# M5531 register map
File version: 1.0
Registers are 32-bit, read-write, reset 0x0 unless marked. A register's access mark holds for its fields unless they carry their own. Offsets are from the block's base; [hi:lo] are bit positions; {n}, {i} and the like mark numbered series; 'fields as' and 'values as' point back to an identical list.

## TRNG_NS — TRNG Register Map
Base 0x50296000
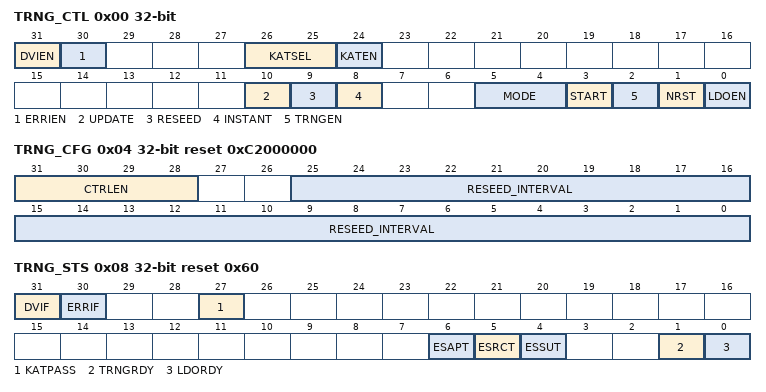
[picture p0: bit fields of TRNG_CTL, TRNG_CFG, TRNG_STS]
0x00 TRNG_CTL — TRNG Control Register
  [31] DVIEN — Data Valid Interrupt Enable Bit
    0=Interrupt Disabled; 1=Interrupt Enabled
  [30] ERRIEN — TRNG Error Interrupt Enable Bit
    0=Error interrupt Disabled; 1=Error interrupt Enabled
  [26:25] KATSEL — CTR_DRBG Known Answer Test Selection
    0=Instantiation testing; 1=Reseed testing; 2=Generation testing
  [24] KATEN — CTR_DRBG Known Answer Test Enable Bit. Note: Do not enable START and KATEN at the same time.
    0=Disabled; 1=Enabled
  [10] UPDATE — CTR_DRBG User Manual Update Function
    0=No effect; 1=Enable CTR_DRBG update function
  [9] RESEED — CTR_DRBG User Manual Reseed Function
    0=No effect; 1=Enable CTR_DRBG reseed function
  [8] INSTANT — CTR_DRBG User Manual Instant Function
    0=No effect; 1=Enable CTR_DRBG instant function
  [5:4] MODE — Random Bit Generator Output Selection
    0=Output data is from entropy (32-bits); 1=Output data is from NRBG (128-bits); 2=Output data is from DRBG (128-bits)
  [3] START — True Random Number Generator Start. Note: Do not enable START and KATEN at the same time. This bit is always 0 when it is read back.
    0=No effect; 1=Start TRNG
  [2] TRNGEN — True Random Number Generator Macro Enable Bit
    0=TRNG macro Disabled; 1=TRNG macro Enabled
  [1] NRST — Negative-edge Trigger Reset
    0=Keep reset; 1=No reset
  [0] LDOEN — LDO Enable Bit
    0=LDO Disabled; 1=LDO Enabled
0x04 TRNG_CFG reset 0xC2000000 — TRNG Configure Register
  [31:28] CTRLEN — CTR_DRBG Bits Length Per Request
  [25:0] RESEED_INTERVAL — Reseed Interval. Maximum number of requests between reseeds. The value is 1 ~ 225 .
0x08 TRNG_STS ro reset 0x60 — TRNG Status Register
  [31] DVIF — Data Valid Interrupt Flag
    0=Data is invalid; 1=Data is valid. A valid random number can be read form TRNG_DATAx
  [30] ERRIF — TRNG Error Interrupt Flag
    0=No TRNG error; 1=TRNGRDY became '0' for a while, TRNG error interrupt
  [27] KATPASS — CTR_DRBG Known Answer Test Pass. Note: When users enable KATEN, they can check this bit after DVIF become '1'.
    0=Test fail; 1=Test pass
  [6] ESAPT — Entropy Source Adaptive Proportion Test
    0=Entropy source is still under testing or test fail; 1=Test pass
  [5] ESRCT — Entropy Source Repetition Count Test
    values as ESAPT
  [4] ESSUT — Entropy Source Start-Up Test
    values as ESAPT
  [1] TRNGRDY — TRNG Ready Signal
    0=True random number generator is not ready; 1=True random number generator is ready
  [0] LDORDY — LDO Ready Signal
    0=LDO is not ready; 1=LDO is ready
{0xC+4i} TRNG_DATA{i} ro (i=0..3) — TRNG Data Output Word {i} Register
  [31:0] DATA — True Random Number Generator Data (Read Only). The DATA stores the output data generated by TRNG, it can be read when DVIF become 1 and can be read only once. TRNG_DATA0 stores Entropy / NRBG word 0 / DRBG word 0. TRNG_DATA1 stores NRBG word 1 / DRBG word 1. TRNG_DATA2 stores NRBG word 2 / DRBG word 2. TRNG_DATA3 stores NRBG word 3 / DRBG word 3.

## EBI_NS — EBI Register Map
Base 0x50230000
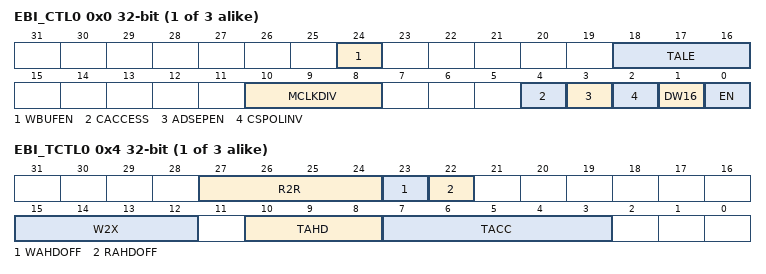
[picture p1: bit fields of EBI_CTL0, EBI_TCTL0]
{0x0+0x10*i} EBI_CTL{i} (i=0..2) — External Bus Interface Bank{i} Control Register
  [24] WBUFEN — EBI Write Buffer Enable Bit. Note: This bit is only available in EBI_CTL0 register. (Write buffer enable of bank0~2 are controlled by this bit)
    0=EBI write buffer Disabled; 1=EBI write buffer Enabled
  [18:16] TALE — Extend Time of ALE. The EBI_ALE high pulse period (tALE) to latch the address can be controlled by TALE. Note: This field is only available in EBI_CTL0 register. (Extend time of ALE of bank0~2 are controlled by these bits)
  [10:8] MCLKDIV — External Output Clock Divider. The frequency of EBI output clock (MCLK) is controlled by MCLKDIV as follow:
    0=HCLK/1; 1=HCLK/2; 2=HCLK/4; 3=HCLK/8; 4=HCLK/16; 5=HCLK/32; 6=HCLK/64; 7=HCLK/128
  [4] CACCESS — Continuous Data Access Mode. When continuous access mode enabled, the tASU, tALE and tLHD cycles are bypass for continuous data transfer request.
    0=Continuous data access mode Disabled; 1=Continuous data access mode Enabled
  [3] ADSEPEN — EBI Address/Data Bus Separate Mode Enable Bit
    0=Address/Data Bus Separate Mode Disabled; 1=Address/Data Bus Separate Mode Enabled
  [2] CSPOLINV — Chip Select Pin Polar Inverse. This bit defines the active level of EBI chip select pin (EBI_nCS).
    0=Chip select pin (EBI_nCS) is active low; 1=Chip select pin (EBI_nCS) is active high
  [1] DW16 — EBI Data Width 16-bit Select. This bit defines if the EBI data width is 8-bit or 16-bit.
    0=EBI data width is 8-bit; 1=EBI data width is 16-bit
  [0] EN — EBI Enable Bit. This bit is the functional enable bit for EBI.
    0=EBI function Disabled; 1=EBI function Enabled
{0x4+0x10*i} EBI_TCTL{i} (i=0..2) — External Bus Interface Bank{i} Timing Control Register
  [27:24] R2R — Idle Cycle Between Read-to-read. This field defines the number of R2R idle cycle. When read action is finished and the next action is going to read, R2R idle cycle is inserted and EBI_nCS return to idle state.
  [23] WAHDOFF — Access Hold Time Disable Control When Write
    0=Data Access Hold Time (tAHD) during EBI writing Enabled; 1=Data Access Hold Time (tAHD) during EBI writing Disabled
  [22] RAHDOFF — Access Hold Time Disable Control When Read
    0=Data Access Hold Time (tAHD) during EBI reading Enabled; 1=Data Access Hold Time (tAHD) during EBI reading Disabled
  [15:12] W2X — Idle Cycle After Write. This field defines the number of W2X idle cycle. When write action is finished, W2X idle cycle is inserted and EBI_nCS return to idle state.
  [10:8] TAHD — EBI Data Access Hold Time. TAHD defines data access hold time (tAHD).
  [7:3] TACC — EBI Data Access Time. TACC defines data access time (tACC).
